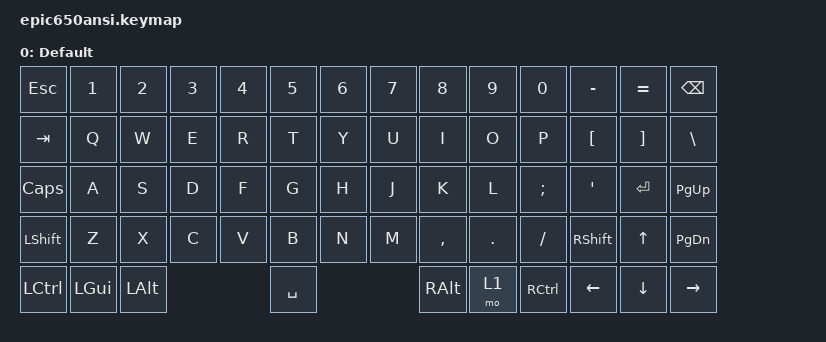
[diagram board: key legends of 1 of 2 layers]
#include <behaviors.dtsi>
#include <dt-bindings/zmk/keys.h>
#include <dt-bindings/zmk/bt.h>
#include <dt-bindings/zmk/outputs.h>

/ {
    keymap0: keymap {
        compatible = "zmk,keymap";

        default_layer {
            display-name = "Default";
            bindings = <
    &kp ESC    &kp N1    &kp N2    &kp N3    &kp N4    &kp N5    &kp N6    &kp N7    &kp N8    &kp N9    &kp N0    &kp MINUS &kp EQUAL &kp BSPC
    &kp TAB    &kp Q     &kp W     &kp E     &kp R     &kp T     &kp Y     &kp U     &kp I     &kp O     &kp P     &kp LBKT  &kp RBKT  &kp BSLH
    &kp CLCK   &kp A     &kp S     &kp D     &kp F     &kp G     &kp H     &kp J     &kp K     &kp L     &kp SEMI  &kp SQT   &kp RET   &kp PG_UP
    &kp LSHFT  &kp Z     &kp X     &kp C     &kp V     &kp B     &kp N     &kp M     &kp COMMA &kp DOT   &kp FSLH  &kp RSHFT &kp UP    &kp PG_DN
    &kp LCTRL  &kp LGUI  &kp LALT                      &kp SPACE                     &kp RALT  &mo 1     &kp RCTRL &kp LEFT  &kp DOWN  &kp RIGHT
            >;
        };

        fn_layer {
            display-name = "Function";
            bindings = <
    &kp GRAVE &kp F1       &kp F2       &kp F3       &kp F4       &kp F5    &kp F6    &kp F7  &kp F8    &kp F9    &kp F10   &kp F11   &kp F12  &bootloader
    &none     &bt BT_SEL 0 &bt BT_SEL 1 &bt BT_SEL 2 &none        &out OUT_TOG        &none   &none     &none     &none     &none     &none    &sys_reset
    &none     &none        &none        &none        &none        &none     &none     &none   &none     &none     &none     &none     &none    &none
    &none     &none        &none        &bt BT_CLR   &none        &none     &none     &none   &none     &none     &none     &none     &none    &none
    &none     &none        &none                                  &none                       &none     &none     &none     &none     &none    &none
            >;
        };

        zmk_studio_1 {
            status = "reserved";
        };

        zmk_studio_2 {
            status = "reserved";
        };
    
    };
};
